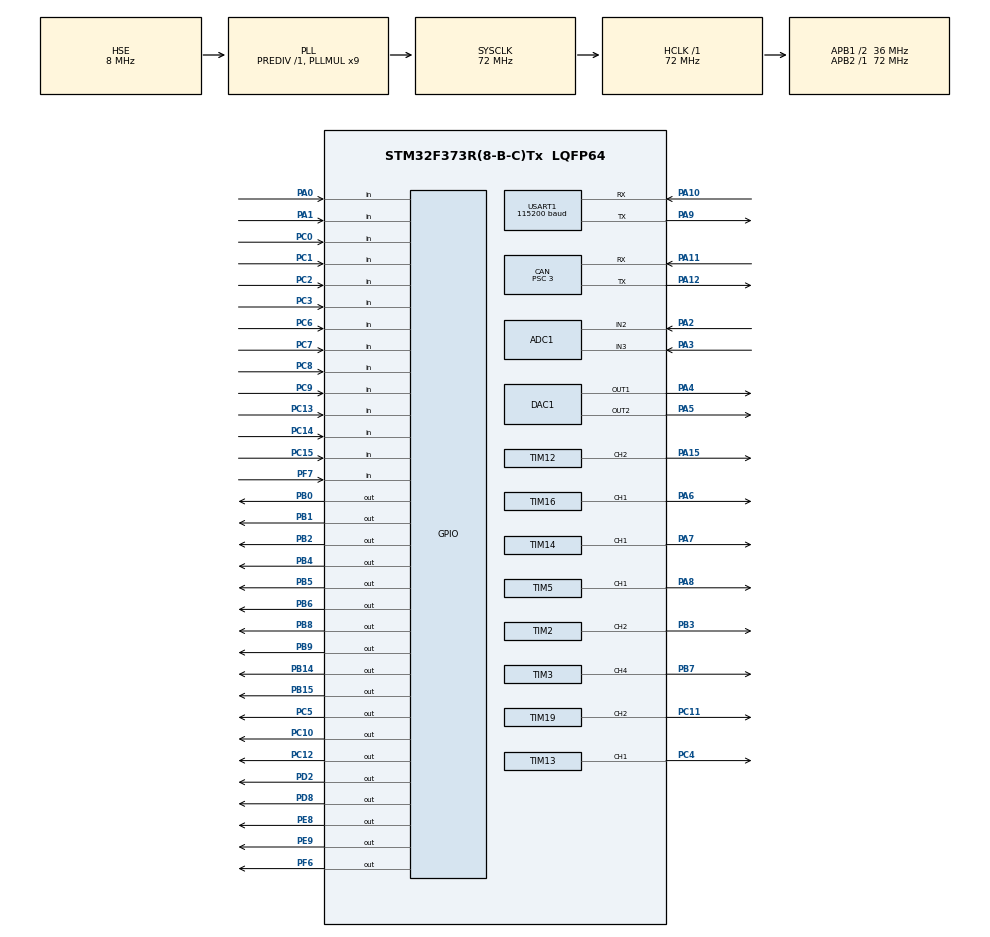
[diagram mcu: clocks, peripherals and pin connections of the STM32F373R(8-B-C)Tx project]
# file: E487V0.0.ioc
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ADC1.Channel-0\#ChannelRegularConversion=ADC_CHANNEL_2
ADC1.Channel-1\#ChannelRegularConversion=ADC_CHANNEL_3
ADC1.ContinuousConvMode=ENABLE
ADC1.DataAlign=ADC_DATAALIGN_RIGHT
ADC1.InjNumberOfConversion=0
ADC1.NbrOfConversion=2
ADC1.NbrOfConversionFlag=1
ADC1.Rank-0\#ChannelRegularConversion=1
ADC1.Rank-1\#ChannelRegularConversion=2
ADC1.SamplingTime-0\#ChannelRegularConversion=ADC_SAMPLETIME_7CYCLES_5
ADC1.SamplingTime-1\#ChannelRegularConversion=ADC_SAMPLETIME_7CYCLES_5
ADC1.master=1
CAN.BS1=CAN_BS1_8TQ
CAN.BS2=CAN_BS2_3TQ
CAN.CalculateBaudRate=999999
CAN.CalculateTimeBit=1000
CAN.CalculateTimeQuantum=83.33333333333334
CAN.NART=ENABLE
CAN.Prescaler=3
CAN.SJW=CAN_SJW_1TQ
Dma.ADC1.0.Direction=DMA_PERIPH_TO_MEMORY
Dma.ADC1.0.Instance=DMA1_Channel1
Dma.ADC1.0.MemDataAlignment=DMA_MDATAALIGN_HALFWORD
Dma.ADC1.0.MemInc=DMA_MINC_ENABLE
Dma.ADC1.0.Mode=DMA_CIRCULAR
Dma.ADC1.0.PeriphDataAlignment=DMA_PDATAALIGN_HALFWORD
Dma.ADC1.0.PeriphInc=DMA_PINC_DISABLE
Dma.ADC1.0.Priority=DMA_PRIORITY_HIGH
Dma.Request0=ADC1
Mcu.Family=STM32F3
Mcu.Name=STM32F373R(8-B-C)Tx
Mcu.Package=LQFP64
NVIC.CAN_RX0_IRQn=true\:0\:0\:false\:false\:true\:true\:true\:true
NVIC.DMA1_Channel1_IRQn=true\:15\:0\:true\:false\:true\:false\:true\:true
NVIC.PriorityGroup=NVIC_PRIORITYGROUP_4
NVIC.TIM12_IRQn=true\:0\:0\:false\:false\:true\:true\:true\:true
NVIC.TIM13_IRQn=true\:0\:0\:false\:false\:true\:true\:true\:true
NVIC.TIM14_IRQn=true\:0\:0\:false\:false\:true\:true\:true\:true
NVIC.TIM16_IRQn=true\:0\:0\:false\:false\:true\:true\:true\:true
NVIC.TIM19_IRQn=true\:0\:0\:false\:false\:true\:true\:true\:true
NVIC.TIM2_IRQn=true\:0\:0\:false\:false\:true\:true\:true\:true
NVIC.TIM3_IRQn=true\:0\:0\:false\:false\:true\:true\:true\:true
NVIC.TIM5_IRQn=true\:0\:0\:false\:false\:true\:true\:true\:true
PA0.Signal=GPIO_Input
PA1.Signal=GPIO_Input
PA10.Mode=Multiprocessor_communication
PA10.Signal=USART1_RX
PA11.GPIO_Speed=GPIO_SPEED_FREQ_HIGH
PA11.Mode=CAN_Activate
PA11.Signal=CAN_RX
PA12.Mode=CAN_Activate
PA12.Signal=CAN_TX
PA13.Mode=Serial_Wire
PA13.Signal=SYS_JTMS-SWDIO
PA14.Mode=Serial_Wire
PA14.Signal=SYS_JTCK-SWCLK
PA15.Signal=S_TIM12_CH2
PA2.Mode=IN2
PA2.Signal=ADC1_IN2
PA3.Mode=IN3
PA3.Signal=ADC1_IN3
PA4.Signal=COMP_DAC11_group
PA5.Signal=COMP_DAC12_group
PA6.Signal=S_TIM16_CH1
PA7.Signal=S_TIM14_CH1
PA8.Signal=S_TIM5_CH1_ETR
PA9.Mode=Multiprocessor_communication
PA9.Signal=USART1_TX
PB0.GPIO_PuPd=GPIO_PULLDOWN
PB0.Signal=GPIO_Output
PB1.GPIO_PuPd=GPIO_PULLDOWN
PB1.Signal=GPIO_Output
PB14.GPIO_PuPd=GPIO_PULLDOWN
PB14.Signal=GPIO_Output
PB15.GPIO_PuPd=GPIO_PULLDOWN
PB15.Signal=GPIO_Output
PB2.GPIO_PuPd=GPIO_PULLDOWN
PB2.Signal=GPIO_Output
PB3.Signal=S_TIM2_CH2
PB4.GPIO_PuPd=GPIO_PULLDOWN
PB4.Signal=GPIO_Output
PB5.GPIO_PuPd=GPIO_PULLDOWN
PB5.Signal=GPIO_Output
PB6.GPIO_PuPd=GPIO_PULLDOWN
PB6.Signal=GPIO_Output
PB7.Signal=S_TIM3_CH4
PB8.GPIO_PuPd=GPIO_PULLDOWN
PB8.Signal=GPIO_Output
PB9.GPIO_PuPd=GPIO_PULLDOWN
PB9.Signal=GPIO_Output
PC0.Signal=GPIO_Input
PC1.Signal=GPIO_Input
PC10.GPIO_PuPd=GPIO_PULLDOWN
PC10.Signal=GPIO_Output
PC11.Signal=S_TIM19_CH2
PC12.GPIO_PuPd=GPIO_PULLDOWN
PC12.Signal=GPIO_Output
PC13.Signal=GPIO_Input
PC14-OSC32_IN.Signal=GPIO_Input
PC15-OSC32_OUT.Signal=GPIO_Input
PC2.Signal=GPIO_Input
PC3.Signal=GPIO_Input
PC4.Signal=S_TIM13_CH1
PC5.GPIO_PuPd=GPIO_PULLDOWN
PC5.Signal=GPIO_Output
PC6.Signal=GPIO_Input
PC7.Signal=GPIO_Input
PC8.Signal=GPIO_Input
PC9.Signal=GPIO_Input
PD2.GPIO_PuPd=GPIO_PULLDOWN
PD2.Signal=GPIO_Output
PD8.GPIO_PuPd=GPIO_PULLUP
PD8.PinState=GPIO_PIN_SET
PD8.Signal=GPIO_Output
PE8.GPIO_PuPd=GPIO_PULLDOWN
PE8.Signal=GPIO_Output
PE9.GPIO_PuPd=GPIO_PULLDOWN
PE9.Signal=GPIO_Output
PF0-OSC_IN.Mode=HSE-External-Oscillator
PF0-OSC_IN.Signal=RCC_OSC_IN
PF1-OSC_OUT.Mode=HSE-External-Oscillator
PF1-OSC_OUT.Signal=RCC_OSC_OUT
PF6.GPIO_PuPd=GPIO_PULLDOWN
PF6.Signal=GPIO_Output
PF7.Signal=GPIO_Input
ProjectManager.HeapSize=0x200
ProjectManager.StackSize=0x400
ProjectManager.TargetToolchain=MDK-ARM V5.32
RCC.AHBFreq_Value=72000000
RCC.APB1CLKDivider=RCC_HCLK_DIV2
RCC.APB1Freq_Value=36000000
RCC.APB1TimFreq_Value=72000000
RCC.APB2Freq_Value=72000000
RCC.APB2TimFreq_Value=72000000
RCC.CortexFreq_Value=72000000
RCC.HCLKFreq_Value=72000000
RCC.HSE_VALUE=8000000
RCC.HSI_VALUE=8000000
RCC.LSE_VALUE=32768
RCC.PLLMUL=RCC_PLL_MUL9
RCC.PLLSourceVirtual=RCC_PLLSOURCE_HSE
RCC.SYSCLKFreq_VALUE=72000000
RCC.SYSCLKSource=RCC_SYSCLKSOURCE_PLLCLK
RCC.USBFreq_Value=72000000
SH.COMP_DAC11_group.0=DAC1_OUT1,DAC_OUT1
SH.COMP_DAC12_group.0=DAC1_OUT2,Enable_DAC_OUT2
SH.S_TIM12_CH2.0=TIM12_CH2,Output Compare2 CH2
SH.S_TIM13_CH1.0=TIM13_CH1,Output Compare1 CH1
SH.S_TIM14_CH1.0=TIM14_CH1,Output Compare1 CH1
SH.S_TIM16_CH1.0=TIM16_CH1,Output Compare1 CH1
SH.S_TIM19_CH2.0=TIM19_CH2,Output Compare2 CH2
SH.S_TIM2_CH2.0=TIM2_CH2,Output Compare2 CH2
SH.S_TIM3_CH4.0=TIM3_CH4,Output Compare4 CH4
SH.S_TIM5_CH1_ETR.0=TIM5_CH1,Output Compare1 CH1
TIM12.AutoReloadPreload=TIM_AUTORELOAD_PRELOAD_ENABLE
TIM12.Channel-Output\ Compare2\ CH2=TIM_CHANNEL_2
TIM12.OCMode_2=TIM_OCMODE_TOGGLE
TIM12.Prescaler=360
TIM13.AutoReloadPreload=TIM_AUTORELOAD_PRELOAD_ENABLE
TIM13.Channel=TIM_CHANNEL_1
TIM13.OCMode_1=TIM_OCMODE_TOGGLE
TIM13.Prescaler=360
TIM14.AutoReloadPreload=TIM_AUTORELOAD_PRELOAD_ENABLE
TIM14.Channel=TIM_CHANNEL_1
TIM14.OCMode_1=TIM_OCMODE_TOGGLE
TIM14.Prescaler=360
TIM16.AutoReloadPreload=TIM_AUTORELOAD_PRELOAD_ENABLE
TIM16.Channel=TIM_CHANNEL_1
TIM16.OCMode_1=TIM_OCMODE_TOGGLE
TIM16.Prescaler=360
TIM19.AutoReloadPreload=TIM_AUTORELOAD_PRELOAD_ENABLE
TIM19.Channel-Output\ Compare2\ CH2=TIM_CHANNEL_2
TIM19.OCMode_2=TIM_OCMODE_TOGGLE
TIM19.Prescaler=360
TIM2.AutoReloadPreload=TIM_AUTORELOAD_PRELOAD_ENABLE
TIM2.Channel-Output\ Compare2\ CH2=TIM_CHANNEL_2
TIM2.OCMode_2=TIM_OCMODE_TOGGLE
TIM2.Period=65536-1
TIM2.Prescaler=360
TIM3.AutoReloadPreload=TIM_AUTORELOAD_PRELOAD_ENABLE
TIM3.Channel-Output\ Compare4\ CH4=TIM_CHANNEL_4
TIM3.OCMode_4=TIM_OCMODE_TOGGLE
TIM3.Prescaler=360
TIM5.AutoReloadPreload=TIM_AUTORELOAD_PRELOAD_ENABLE
TIM5.Channel-Output\ Compare1\ CH1=TIM_CHANNEL_1
TIM5.OCMode_1=TIM_OCMODE_TOGGLE
TIM5.Prescaler=360
USART1.BaudRate=115200
USART1.RxPinLevelInvertParam=ADVFEATURE_RXINV_DISABLE
USART1.VirtualMode-Multiprocessor_communication=VM_ASYNC
VP_TIM13_VS_ClockSourceINT.Mode=Enable_Timer
VP_TIM14_VS_ClockSourceINT.Mode=Enable_Timer
VP_TIM16_VS_ClockSourceINT.Mode=Enable_Timer
VP_TIM19_VS_ClockSourceINT.Mode=Internal
VP_TIM2_VS_ClockSourceINT.Mode=Internal
VP_TIM3_VS_ClockSourceINT.Mode=Internal
VP_TIM5_VS_ClockSourceINT.Mode=Internal
board=custom

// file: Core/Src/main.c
/* USER CODE BEGIN Header */
/**
  ******************************************************************************
  * @file           : main.c
  * @brief          : Main program body
  ******************************************************************************
  * @attention
  *
  * Copyright (c) 2023 STMicroelectronics.
  * All rights reserved.
  *
  * This software is licensed under terms that can be found in the LICENSE file
  * in the root directory of this software component.
  * If no LICENSE file comes with this software, it is provided AS-IS.
  *
  ******************************************************************************
  */
/* USER CODE END Header */
#include "main.h"
#include "adc.h"
#include "can.h"
#include "dac.h"
#include "dma.h"
#include "tim.h"
#include "usart.h"
#include "gpio.h"

/* USER CODE BEGIN Includes */
#include "MotorIo.h"
#include "MotorStep.h"
#include "MotorMove.h"
#include "CanCommand.h"
/* USER CODE END Includes */

void SystemClock_Config(void);

/* USER CODE BEGIN 0 */
uint16_t adc[10][2];

/* USER CODE END 0 */

int main(void)
{

  /* MCU Configuration--------------------------------------------------------*/

  /* Reset of all peripherals, Initializes the Flash interface and the Systick. */
  HAL_Init();

  /* Configure the system clock */
  SystemClock_Config();

  /* Initialize all configured peripherals */
  MX_GPIO_Init();
  MX_DMA_Init();
  MX_ADC1_Init();
  MX_CAN_Init();
  MX_DAC1_Init();
  MX_USART1_UART_Init();
  MX_TIM2_Init();
  MX_TIM3_Init();
  MX_TIM5_Init();
  MX_TIM13_Init();
  MX_TIM16_Init();
  MX_TIM19_Init();
  MX_TIM12_Init();
  MX_TIM14_Init();
  /* USER CODE BEGIN 2 */
  HAL_Delay(40);
  MotorInit();
  HAL_ADCEx_Calibration_Start(&hadc1);
  HAL_ADC_Start_DMA(&hadc1,(uint32_t*)adc,20);

  MOTOREN_NO();

  /* USER CODE END 2 */

  /* Infinite loop */
  /* USER CODE BEGIN WHILE */
  while (1)
  {
    CanCmdRevAnalysis();
    MotorHomeZeroTask_Loop();
    MotorClockCurrentSet_loop();
    /* USER CODE END WHILE */

  }
}

void SystemClock_Config(void)
{
  RCC_OscInitTypeDef RCC_OscInitStruct = {0};
  RCC_ClkInitTypeDef RCC_ClkInitStruct = {0};
  RCC_PeriphCLKInitTypeDef PeriphClkInit = {0};

  /** Initializes the RCC Oscillators according to the specified parameters
  * in the RCC_OscInitTypeDef structure.
  */
  RCC_OscInitStruct.OscillatorType = RCC_OSCILLATORTYPE_HSE;
  RCC_OscInitStruct.HSEState = RCC_HSE_ON;
  RCC_OscInitStruct.HSEPredivValue = RCC_HSE_PREDIV_DIV1;
  RCC_OscInitStruct.HSIState = RCC_HSI_ON;
  RCC_OscInitStruct.PLL.PLLState = RCC_PLL_ON;
  RCC_OscInitStruct.PLL.PLLSource = RCC_PLLSOURCE_HSE;
  RCC_OscInitStruct.PLL.PLLMUL = RCC_PLL_MUL9;
  if (HAL_RCC_OscConfig(&RCC_OscInitStruct) != HAL_OK)
  {
    Error_Handler();
  }

  /** Initializes the CPU, AHB and APB buses clocks
  */
  RCC_ClkInitStruct.ClockType = RCC_CLOCKTYPE_HCLK|RCC_CLOCKTYPE_SYSCLK
                              |RCC_CLOCKTYPE_PCLK1|RCC_CLOCKTYPE_PCLK2;
  RCC_ClkInitStruct.SYSCLKSource = RCC_SYSCLKSOURCE_PLLCLK;
  RCC_ClkInitStruct.AHBCLKDivider = RCC_SYSCLK_DIV1;
  RCC_ClkInitStruct.APB1CLKDivider = RCC_HCLK_DIV2;
  RCC_ClkInitStruct.APB2CLKDivider = RCC_HCLK_DIV1;

  if (HAL_RCC_ClockConfig(&RCC_ClkInitStruct, FLASH_LATENCY_2) != HAL_OK)
  {
    Error_Handler();
  }
  PeriphClkInit.PeriphClockSelection = RCC_PERIPHCLK_USART1|RCC_PERIPHCLK_ADC1;
  PeriphClkInit.Usart1ClockSelection = RCC_USART1CLKSOURCE_PCLK2;
  PeriphClkInit.Adc1ClockSelection = RCC_ADC1PCLK2_DIV2;

  if (HAL_RCCEx_PeriphCLKConfig(&PeriphClkInit) != HAL_OK)
  {
    Error_Handler();
  }
}

void Error_Handler(void)
{
  __disable_irq();
  while (1)
  {
  }
}
